# psc3 register map
Vendor: Infineon Technologies; Series: PSC3; File version: 1.0
CPU: CM33 r0p1, little endian, MPU, FPU, DSP, VTOR, 3 interrupt priority bits, 140 interrupts
Registers are 32-bit, read-write, reset 0x0 unless marked. A register's access mark holds for its fields unless they carry their own. Offsets are from the block's base; [hi:lo] are bit positions; 'fields as' and 'values as' point back to an identical list; <NAME> marks a mode.

## LPCOMP — Low Power Comparators
Base 0x42430000
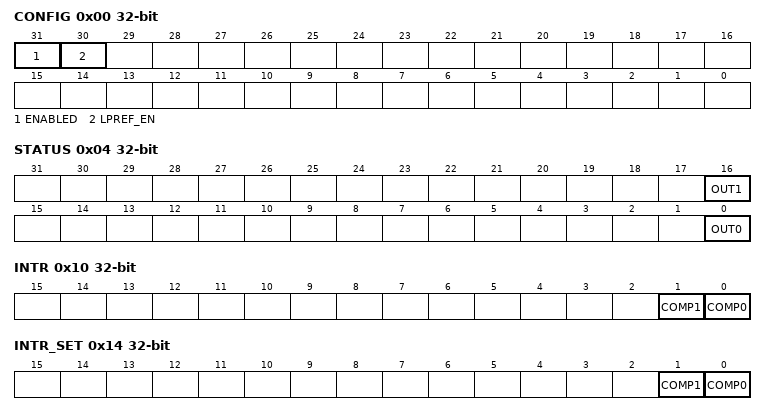
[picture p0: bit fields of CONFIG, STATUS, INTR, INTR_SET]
0x00 CONFIG — LPCOMP Configuration Register
  [31] ENABLED — - 0: LPCOMP disabled (puts analog in power down, opens all switches, all clocks turned off) - 1: LPCOMP enabled
  [30] LPREF_EN — Enable the local reference generator circuit to generate the local Vref and Ibias. Ibias current is an alternative to the reference current IREF generated by SRSS. This bit must be set for System Deep Sleep and System Hibernate operation.
0x04 STATUS ro — LPCOMP Status Register
  [16] OUT1 — Current output value of the comparator 1.
  [0] OUT0 — Current output value of the comparator 0.
0x10 INTR — LPCOMP Interrupt request register
  [1] COMP1 write-1-clears — Comparator 1 Interrupt: hardware sets this interrupt when comparator 1 triggers. Write with '1' to clear bit.
  [0] COMP0 write-1-clears — Comparator 0 Interrupt: hardware sets this interrupt when comparator 0 triggers. Write with '1' to clear bit.
0x14 INTR_SET — LPCOMP Interrupt set register
  [1] COMP1 write-1-sets — Write with '1' to set corresponding bit in interrupt request register.
  [0] COMP0 write-1-sets — Write with '1' to set corresponding bit in interrupt request register.
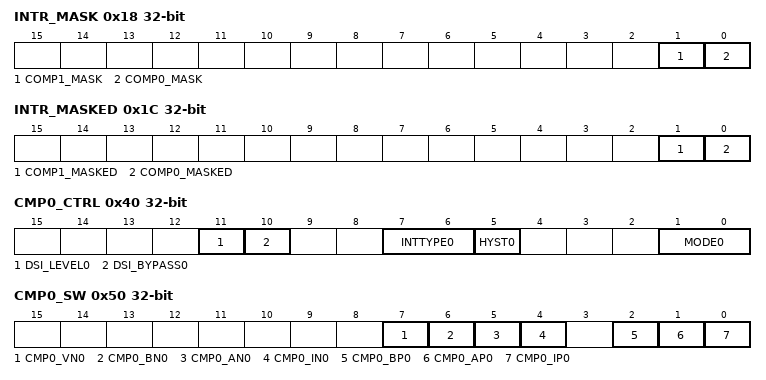
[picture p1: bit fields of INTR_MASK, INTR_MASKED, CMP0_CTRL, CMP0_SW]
0x18 INTR_MASK — LPCOMP Interrupt request mask
  [1] COMP1_MASK — Mask bit for corresponding bit in interrupt request register.
  [0] COMP0_MASK — Mask bit for corresponding bit in interrupt request register.
0x1C INTR_MASKED ro — LPCOMP Interrupt request masked
  [1] COMP1_MASKED — Logical and of corresponding request and mask bits.
  [0] COMP0_MASKED — Logical and of corresponding request and mask bits.
0x40 CMP0_CTRL — Comparator 0 control Register
  [11] DSI_LEVEL0 — Synchronous comparator output (trigger): 0=pulse 1=level
  [10] DSI_BYPASS0 — Asynchronous: bypass comparator output synchronization: 0=synchronize (level or pulse) 1=bypass (output async) Note that in System Deep Sleep mode, this bit needs to be set to observe the output on the dedicated pin.
  [7:6] INTTYPE0
    0=DISABLE (Disabled, no interrupts will be detected); 1=RISING (Rising edge); 2=FALLING (Falling edge); 3=BOTH (Both rising and falling edges)
  [5] HYST0 — Add hysteresis to the comparator 0= Disable Hysteresis 1= Enable Hysteresis
  [1:0] MODE0
    0=OFF; 1=ULP (Ultra lowpower operating mode (uses less power, < 300nA), must be used for DeepSleep or Hibernate. Only in this mode a local iref will be used.); 2=LP (Low Power operating mode (uses more power, <10uA @@@ TBD). In this mode the iref from SRSS will be used.); 3=NORMAL (Normal, full speed power operating mode (uses <150uA). In this mode the iref from SRSS will be used.)
0x50 CMP0_SW — Comparator 0 switch control
  [7] CMP0_VN0 write-1-sets — Comparator 0 negative terminal switch to local Vref (LPREF_EN must be set)
  [6] CMP0_BN0 write-1-sets — Comparator 0 negative terminal switch to amuxbusB
  [5] CMP0_AN0 write-1-sets — Comparator 0 negative terminal switch to amuxbusA
  [4] CMP0_IN0 write-1-sets — Comparator 0 negative terminal isolation switch to GPIO
  [2] CMP0_BP0 write-1-sets — Comparator 0 positive terminal switch to amuxbusB
  [1] CMP0_AP0 write-1-sets — Comparator 0 positive terminal switch to amuxbusA
  [0] CMP0_IP0 write-1-sets — Comparator 0 positive terminal isolation switch to GPIO
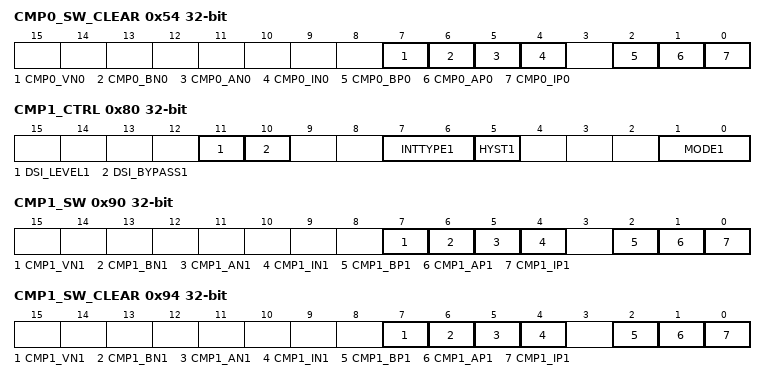
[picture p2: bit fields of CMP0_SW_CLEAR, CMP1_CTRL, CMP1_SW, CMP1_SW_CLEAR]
0x54 CMP0_SW_CLEAR — Comparator 0 switch control clear
  [7] CMP0_VN0 write-1-clears — see corresponding bit in CMP0_SW
  [6] CMP0_BN0 write-1-clears — see corresponding bit in CMP0_SW
  [5] CMP0_AN0 write-1-clears — see corresponding bit in CMP0_SW
  [4] CMP0_IN0 write-1-clears — see corresponding bit in CMP0_SW
  [2] CMP0_BP0 write-1-clears — see corresponding bit in CMP0_SW
  [1] CMP0_AP0 write-1-clears — see corresponding bit in CMP0_SW
  [0] CMP0_IP0 write-1-clears — see corresponding bit in CMP0_SW
0x80 CMP1_CTRL — Comparator 1 control Register
  [11] DSI_LEVEL1 — Synchronous comparator output (trigger): 0=pulse 1=level
  [10] DSI_BYPASS1 — Asynchronous: bypass comparator output synchronization: 0=synchronize (level or pulse) 1=bypass (output async) Note that in System Deep Sleep mode, this bit needs to be set to observe the output on the dedicated pin.
  [7:6] INTTYPE1
    values as CMP0_CTRL.INTTYPE0
  [5] HYST1 — Add hysteresis to the comparator 0= Disable Hysteresis 1= Enable Hysteresis
  [1:0] MODE1
    values as CMP0_CTRL.MODE0
0x90 CMP1_SW — Comparator 1 switch control
  [7] CMP1_VN1 write-1-sets — Comparator 1 negative terminal switch to local Vref (LPREF_EN must be set)
  [6] CMP1_BN1 write-1-sets — Comparator 1 negative terminal switch to amuxbusB
  [5] CMP1_AN1 write-1-sets — Comparator 1 negative terminal switch to amuxbusA
  [4] CMP1_IN1 write-1-sets — Comparator 1 negative terminal isolation switch to GPIO
  [2] CMP1_BP1 write-1-sets — Comparator 1 positive terminal switch to amuxbusB
  [1] CMP1_AP1 write-1-sets — Comparator 1 positive terminal switch to amuxbusA
  [0] CMP1_IP1 write-1-sets — Comparator 1 positive terminal isolation switch to GPIO
0x94 CMP1_SW_CLEAR — Comparator 1 switch control clear
  [7] CMP1_VN1 write-1-clears — see corresponding bit in CMP1_SW
  [6] CMP1_BN1 write-1-clears — see corresponding bit in CMP1_SW
  [5] CMP1_AN1 write-1-clears — see corresponding bit in CMP1_SW
  [4] CMP1_IN1 write-1-clears — see corresponding bit in CMP1_SW
  [2] CMP1_BP1 write-1-clears — see corresponding bit in CMP1_SW
  [1] CMP1_AP1 write-1-clears — see corresponding bit in CMP1_SW
  [0] CMP1_IP1 write-1-clears — see corresponding bit in CMP1_SW
